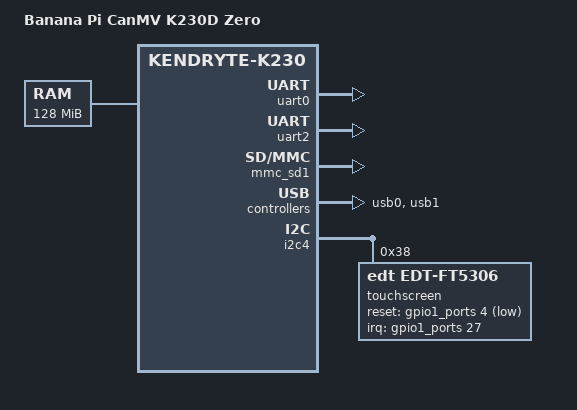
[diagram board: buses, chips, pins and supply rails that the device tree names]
// SPDX-License-Identifier: GPL-2.0 OR MIT
/*
 * Copyright (C) 2024 Yangyu Chen <cyy@cyyself.name>
 */

#include "k230.dtsi"
#include "display-st7701-480x800.dtsi"

/ {
	model = "Banana Pi CanMV K230D Zero";
	compatible = "canaan,canmv-k230", "canaan,kendryte-k230";

	aliases {
		serial2 = &uart2;
	};

	chosen {
		stdout-path = "serial0:115200n8";
		bootargs = "root=/dev/mmcblk0p2 loglevel=8 rw rootdelay=4 \
						rootfstype=ext4 console=ttyS0,115200  earlycon=sbi";
	};

	ddr: memory@0 {
		device_type = "memory";
		reg = <0x0 0x0 0x0 0x8000000>;
	};
};

&uart0 {
	status = "okay";
};
&uart2 {
	status = "okay";
};
&mmc_sd1{
	status = "okay";
	no-1-8-v;
	cap-sd-highspeed;
	mshc_ctrl_r = <0x00>;
};
&usb0 {
	status = "okay";
};
&usb1 {
	status = "okay";
};

&i2c4 {
	status = "okay";
	touchscreen@38 {
		compatible = "edt,edt-ft5306";
		reg = <0x38>;
		reset-gpios = <&gpio1_ports 4 GPIO_ACTIVE_LOW>;
		interrupt-parent = <&gpio1_ports>;
		interrupts = <27 IRQ_TYPE_EDGE_FALLING>;
	};
};

&lcd {
	dsi_reset-gpios = <&gpio1_ports 5 GPIO_ACTIVE_HIGH>;
};
